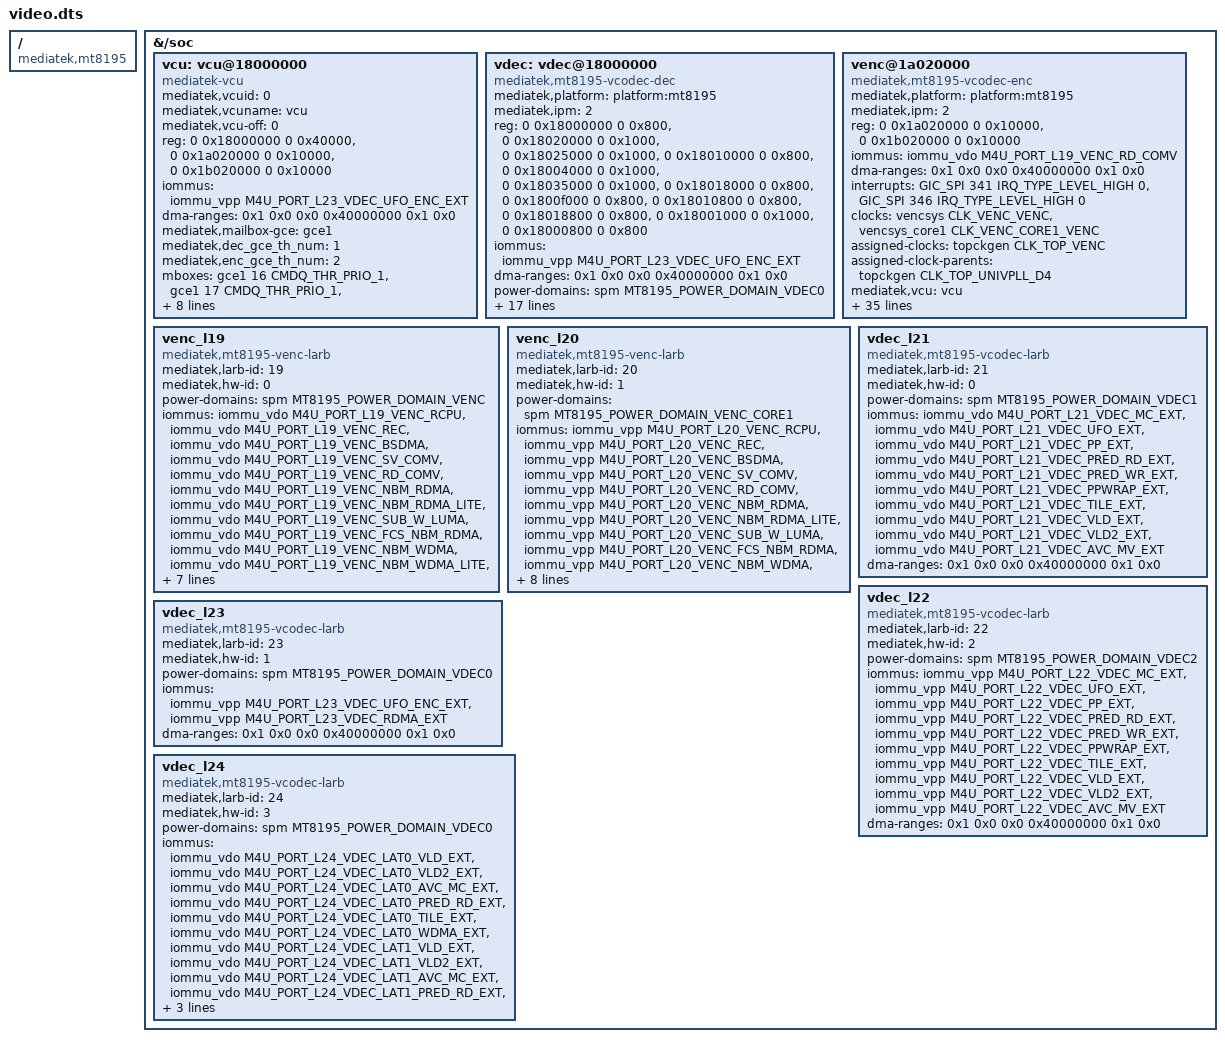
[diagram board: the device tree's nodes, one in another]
// SPDX-License-Identifier: (GPL-2.0 OR MIT)
/*
 * Copyright (c) 2021 MediaTek Inc.
 * Author: Macross Chen <macross.chen@mediatek.com>
 */

/dts-v1/;
/plugin/;

#include <dt-bindings/clock/mt8195-clk.h>
#include <dt-bindings/gce/mt8195-gce.h>
#include <dt-bindings/interrupt-controller/arm-gic.h>
#include <dt-bindings/interrupt-controller/irq.h>
#include <dt-bindings/memory/mt8195-memory-port.h>
#include <dt-bindings/power/mt8195-power.h>

/ {
	compatible = "mediatek,mt8195";
 
	fragment@0 {
		target-path = "/soc";
		__overlay__ {
			vcu: vcu@18000000 {
				compatible = "mediatek-vcu";
				mediatek,vcuid = <0>;
				mediatek,vcuname = "vcu";
				mediatek,vcu-off  = <0>;
				reg = <0 0x18000000 0 0x40000>,/* VDEC_BASE */
					  <0 0x1a020000 0 0x10000>,/* VENC_BASE */
					  <0 0x1b020000 0 0x10000>;/* VENC_C1_BASE */
				iommus = <&iommu_vpp M4U_PORT_L23_VDEC_UFO_ENC_EXT>;
				dma-ranges = <0x1 0x0 0x0 0x40000000 0x1 0x0>;
				mediatek,mailbox-gce = <&gce1>;
				mediatek,dec_gce_th_num = <1>;
				mediatek,enc_gce_th_num = <2>;
				mboxes = <&gce1 16 CMDQ_THR_PRIO_1>,
					 <&gce1 17 CMDQ_THR_PRIO_1>,
					 <&gce1 18 CMDQ_THR_PRIO_1>;
				gce-event-names = "venc_eof",
						  "venc_eof_c1",
						  "venc_wp_2nd_done",
						  "venc_wp_3nd_done";

				gce-events = <CMDQ_EVENT_VENC_TOP_FRAME_DONE>,
						 <CMDQ_EVENT_VENC_CORE1_TOP_FRAME_DONE>,
						 <CMDQ_EVENT_VENC_TOP_WP_2ND_STAGE_DONE>,
						 <CMDQ_EVENT_VENC_TOP_WP_3RD_STAGE_DONE>;

				gce-gpr = <GCE_GPR_R10>, <GCE_GPR_R11>;
			};

			vdec: vdec@18000000 {
				compatible = "mediatek,mt8195-vcodec-dec";
				mediatek,platform = "platform:mt8195";
				mediatek,ipm = <2>;
				reg =   <0 0x18000000 0 0x800>,/* VDEC_BASE */
					<0 0x18020000 0 0x1000>,/* VDEC_VLD */
					<0 0x18025000 0 0x1000>,/* VDEC_MISC */
					<0 0x18010000 0 0x800>,/* VDEC_LAT_MISC */
					<0 0x18004000 0 0x1000>,/* VDEC_RACING_CTRL */
					<0 0x18035000 0 0x1000>,/* VDEC_CORE1_MISC */
					<0 0x18018000 0 0x800>,/* VDEC_LAT1_MISC */
					<0 0x1800f000 0 0x800>,/* VDEC_SOC_GCON */
					<0 0x18010800 0 0x800>,/* VDEC_LAT_WDMA */
					<0 0x18018800 0 0x800>,/* VDEC_LAT1_WDMA */
					<0 0x18001000 0 0x1000>,/* VDEC_LAT_TOP */
					<0 0x18000800 0 0x800>;/* VDEC_UFO_ENC */
				reg-names = "VDEC_BASE",
					"VDEC_VLD",
					"VDEC_MISC",
					"VDEC_LAT_MISC",
					"VDEC_RACING_CTRL",
					"VDEC_CORE1_MISC",
					"VDEC_LAT1_MISC",
					"VDEC_SOC_GCON",
					"VDEC_LAT_WDMA",
					"VDEC_LAT1_WDMA",
					"VDEC_LAT_TOP",
					"VDEC_UFO_ENC";
				iommus = <&iommu_vpp M4U_PORT_L23_VDEC_UFO_ENC_EXT>;
				dma-ranges = <0x1 0x0 0x0 0x40000000 0x1 0x0>;
				power-domains = <&spm MT8195_POWER_DOMAIN_VDEC0>;/* SOC */
				interrupts = <GIC_SPI 707 IRQ_TYPE_LEVEL_HIGH 0>,
						 <GIC_SPI 708 IRQ_TYPE_LEVEL_HIGH 0>,
						 <GIC_SPI 709 IRQ_TYPE_LEVEL_HIGH 0>,
						 <GIC_SPI 710 IRQ_TYPE_LEVEL_HIGH 0>,
						 <GIC_SPI 711 IRQ_TYPE_LEVEL_HIGH 0>;
				clocks = <&vdecsys_soc CLK_VDEC_SOC_LARB1>,
					 <&vdecsys_soc CLK_VDEC_SOC_LAT>,
					 <&vdecsys_soc CLK_VDEC_SOC_VDEC>,
					 <&vdecsys CLK_VDEC_LARB1>,
					 <&vdecsys CLK_VDEC_VDEC>,
					 <&vdecsys_core1 CLK_VDEC_CORE1_LARB1>,
					 <&vdecsys_core1 CLK_VDEC_CORE1_VDEC>;
				clock-names = "SOC_MT_CG_LARB1",
					 "LAT_MT_CG_VDEC",
					 "SOC_MT_CG_VDEC",
					 "CORE_MT_CG_LARB1",
					 "CORE_MT_CG_VDEC",
					 "CORE_MT_CG_CORE1_LARB1",
					 "CORE_MT_CG_CORE1_VDEC";
				assigned-clocks = <&topckgen CLK_TOP_VDEC>;
				assigned-clock-parents = <&apmixedsys CLK_APMIXED_VDECPLL>;
				assigned-clock-rates = <680000000>;
				mediatek,vcu = <&vcu>;
			};

			venc@1a020000 {
				compatible = "mediatek,mt8195-vcodec-enc";
				mediatek,platform = "platform:mt8195";
				mediatek,ipm = <2>;
				reg = <0 0x1a020000 0 0x10000>,/* VENC_C0 */
					  <0 0x1b020000 0 0x10000>;/* VENC_C1 */
				reg-names = "VENC_SYS",
					"VENC_C1_SYS";
				iommus = <&iommu_vdo M4U_PORT_L19_VENC_RD_COMV>;
				dma-ranges = <0x1 0x0 0x0 0x40000000 0x1 0x0>;
				interrupts = <GIC_SPI 341 IRQ_TYPE_LEVEL_HIGH 0>,
						 <GIC_SPI 346 IRQ_TYPE_LEVEL_HIGH 0>;
				clocks = <&vencsys CLK_VENC_VENC>,
					 <&vencsys_core1 CLK_VENC_CORE1_VENC>;
				clock-names = "MT_CG_VENC0",
						  "MT_CG_VENC1";
				assigned-clocks = <&topckgen CLK_TOP_VENC>;
				assigned-clock-parents = <&topckgen CLK_TOP_UNIVPLL_D4>;
				mediatek,vcu = <&vcu>;

				port-arg-num = <3>;
				port-def = <0 M4U_PORT_L19_VENC_RCPU 0>,
					 <0 M4U_PORT_L19_VENC_REC 0>,
					 <0 M4U_PORT_L19_VENC_BSDMA 0>,
					 <0 M4U_PORT_L19_VENC_SV_COMV 0>,
					 <0 M4U_PORT_L19_VENC_RD_COMV 0>,
					 <0 M4U_PORT_L19_VENC_NBM_RDMA 1>,
					 <0 M4U_PORT_L19_VENC_NBM_RDMA_LITE 1>,
					 <0 M4U_PORT_L19_VENC_SUB_W_LUMA 0>,
					 <0 M4U_PORT_L19_VENC_FCS_NBM_RDMA 1>,
					 <0 M4U_PORT_L19_VENC_NBM_WDMA 1>,
					 <0 M4U_PORT_L19_VENC_NBM_WDMA_LITE 1>,
					 <0 M4U_PORT_L19_VENC_FCS_NBM_WDMA 1>,
					 <0 M4U_PORT_L19_VENC_CUR_LUMA 0>,
					 <0 M4U_PORT_L19_VENC_CUR_CHROMA 0>,
					 <0 M4U_PORT_L19_VENC_REF_LUMA 0>,
					 <0 M4U_PORT_L19_VENC_REF_CHROMA 0>,
					 <0 M4U_PORT_L19_VENC_SUB_R_CHROMA 0>,
					 <1 M4U_PORT_L20_VENC_RCPU 0>,
					 <1 M4U_PORT_L20_VENC_REC 0>,
					 <1 M4U_PORT_L20_VENC_BSDMA 0>,
					 <1 M4U_PORT_L20_VENC_SV_COMV 0>,
					 <1 M4U_PORT_L20_VENC_RD_COMV 0>,
					 <1 M4U_PORT_L20_VENC_NBM_RDMA 1>,
					 <1 M4U_PORT_L20_VENC_NBM_RDMA_LITE 1>,
					 <1 M4U_PORT_L20_VENC_SUB_W_LUMA 0>,
					 <1 M4U_PORT_L20_VENC_FCS_NBM_RDMA 1>,
					 <1 M4U_PORT_L20_VENC_NBM_WDMA 1>,
					 <1 M4U_PORT_L20_VENC_NBM_WDMA_LITE 1>,
					 <1 M4U_PORT_L20_VENC_FCS_NBM_WDMA 1>,
					 <1 M4U_PORT_L20_VENC_CUR_LUMA 0>,
					 <1 M4U_PORT_L20_VENC_CUR_CHROMA 0>,
					 <1 M4U_PORT_L20_VENC_REF_LUMA 0>,
					 <1 M4U_PORT_L20_VENC_REF_CHROMA 0>,
					 <1 M4U_PORT_L20_VENC_SUB_R_CHROMA 0>;
			};

			venc_l19 {
				compatible = "mediatek,mt8195-venc-larb";
				mediatek,larb-id = <19>;
				mediatek,hw-id = <0>;
				power-domains = <&spm MT8195_POWER_DOMAIN_VENC>;
				iommus = <&iommu_vdo M4U_PORT_L19_VENC_RCPU>,
					 <&iommu_vdo M4U_PORT_L19_VENC_REC>,
					 <&iommu_vdo M4U_PORT_L19_VENC_BSDMA>,
					 <&iommu_vdo M4U_PORT_L19_VENC_SV_COMV>,
					 <&iommu_vdo M4U_PORT_L19_VENC_RD_COMV>,
					 <&iommu_vdo M4U_PORT_L19_VENC_NBM_RDMA>,
					 <&iommu_vdo M4U_PORT_L19_VENC_NBM_RDMA_LITE>,
					 <&iommu_vdo M4U_PORT_L19_VENC_SUB_W_LUMA>,
					 <&iommu_vdo M4U_PORT_L19_VENC_FCS_NBM_RDMA>,
					 <&iommu_vdo M4U_PORT_L19_VENC_NBM_WDMA>,
					 <&iommu_vdo M4U_PORT_L19_VENC_NBM_WDMA_LITE>,
					 <&iommu_vdo M4U_PORT_L19_VENC_FCS_NBM_WDMA>,
					 <&iommu_vdo M4U_PORT_L19_VENC_CUR_LUMA>,
					 <&iommu_vdo M4U_PORT_L19_VENC_CUR_CHROMA>,
					 <&iommu_vdo M4U_PORT_L19_VENC_REF_LUMA>,
					 <&iommu_vdo M4U_PORT_L19_VENC_REF_CHROMA>,
					 <&iommu_vdo M4U_PORT_L19_VENC_SUB_R_CHROMA>;
				dma-ranges = <0x1 0x0 0x0 0x40000000 0x1 0x0>;
			};

			venc_l20 {
				compatible = "mediatek,mt8195-venc-larb";
				mediatek,larb-id = <20>;
				mediatek,hw-id = <1>;
				power-domains = <&spm MT8195_POWER_DOMAIN_VENC_CORE1>;
				iommus = <&iommu_vpp M4U_PORT_L20_VENC_RCPU>,
					 <&iommu_vpp M4U_PORT_L20_VENC_REC>,
					 <&iommu_vpp M4U_PORT_L20_VENC_BSDMA>,
					 <&iommu_vpp M4U_PORT_L20_VENC_SV_COMV>,
					 <&iommu_vpp M4U_PORT_L20_VENC_RD_COMV>,
					 <&iommu_vpp M4U_PORT_L20_VENC_NBM_RDMA>,
					 <&iommu_vpp M4U_PORT_L20_VENC_NBM_RDMA_LITE>,
					 <&iommu_vpp M4U_PORT_L20_VENC_SUB_W_LUMA>,
					 <&iommu_vpp M4U_PORT_L20_VENC_FCS_NBM_RDMA>,
					 <&iommu_vpp M4U_PORT_L20_VENC_NBM_WDMA>,
					 <&iommu_vpp M4U_PORT_L20_VENC_NBM_WDMA_LITE>,
					 <&iommu_vpp M4U_PORT_L20_VENC_FCS_NBM_WDMA>,
					 <&iommu_vpp M4U_PORT_L20_VENC_CUR_LUMA>,
					 <&iommu_vpp M4U_PORT_L20_VENC_CUR_CHROMA>,
					 <&iommu_vpp M4U_PORT_L20_VENC_REF_LUMA>,
					 <&iommu_vpp M4U_PORT_L20_VENC_REF_CHROMA>,
					 <&iommu_vpp M4U_PORT_L20_VENC_SUB_R_CHROMA>;
				dma-ranges = <0x1 0x0 0x0 0x40000000 0x1 0x0>;
			};

			vdec_l21 {
				compatible = "mediatek,mt8195-vcodec-larb";
				mediatek,larb-id = <21>;
				mediatek,hw-id = <0>;
				power-domains = <&spm MT8195_POWER_DOMAIN_VDEC1>;/* core0 */
				iommus = <&iommu_vdo M4U_PORT_L21_VDEC_MC_EXT>,
					 <&iommu_vdo M4U_PORT_L21_VDEC_UFO_EXT>,
					 <&iommu_vdo M4U_PORT_L21_VDEC_PP_EXT>,
					 <&iommu_vdo M4U_PORT_L21_VDEC_PRED_RD_EXT>,
					 <&iommu_vdo M4U_PORT_L21_VDEC_PRED_WR_EXT>,
					 <&iommu_vdo M4U_PORT_L21_VDEC_PPWRAP_EXT>,
					 <&iommu_vdo M4U_PORT_L21_VDEC_TILE_EXT>,
					 <&iommu_vdo M4U_PORT_L21_VDEC_VLD_EXT>,
					 <&iommu_vdo M4U_PORT_L21_VDEC_VLD2_EXT>,
					 <&iommu_vdo M4U_PORT_L21_VDEC_AVC_MV_EXT>;
				dma-ranges = <0x1 0x0 0x0 0x40000000 0x1 0x0>;
			};

			vdec_l22 {
				compatible = "mediatek,mt8195-vcodec-larb";
				mediatek,larb-id = <22>;
				mediatek,hw-id = <2>;
				power-domains = <&spm MT8195_POWER_DOMAIN_VDEC2>;/* core1 */
				iommus = <&iommu_vpp M4U_PORT_L22_VDEC_MC_EXT>,
					 <&iommu_vpp M4U_PORT_L22_VDEC_UFO_EXT>,
					 <&iommu_vpp M4U_PORT_L22_VDEC_PP_EXT>,
					 <&iommu_vpp M4U_PORT_L22_VDEC_PRED_RD_EXT>,
					 <&iommu_vpp M4U_PORT_L22_VDEC_PRED_WR_EXT>,
					 <&iommu_vpp M4U_PORT_L22_VDEC_PPWRAP_EXT>,
					 <&iommu_vpp M4U_PORT_L22_VDEC_TILE_EXT>,
					 <&iommu_vpp M4U_PORT_L22_VDEC_VLD_EXT>,
					 <&iommu_vpp M4U_PORT_L22_VDEC_VLD2_EXT>,
					 <&iommu_vpp M4U_PORT_L22_VDEC_AVC_MV_EXT>;
				dma-ranges = <0x1 0x0 0x0 0x40000000 0x1 0x0>;
			};

			vdec_l23 {
				compatible = "mediatek,mt8195-vcodec-larb";
				mediatek,larb-id = <23>;
				mediatek,hw-id = <1>;
				power-domains = <&spm MT8195_POWER_DOMAIN_VDEC0>;/* soc */
				iommus = <&iommu_vpp M4U_PORT_L23_VDEC_UFO_ENC_EXT>,
					 <&iommu_vpp M4U_PORT_L23_VDEC_RDMA_EXT>;
				dma-ranges = <0x1 0x0 0x0 0x40000000 0x1 0x0>;
			};

			vdec_l24 {
				compatible = "mediatek,mt8195-vcodec-larb";
				mediatek,larb-id = <24>;
				mediatek,hw-id = <3>;
				power-domains = <&spm MT8195_POWER_DOMAIN_VDEC0>;/* soc */
				iommus = <&iommu_vdo M4U_PORT_L24_VDEC_LAT0_VLD_EXT>,
					 <&iommu_vdo M4U_PORT_L24_VDEC_LAT0_VLD2_EXT>,
					 <&iommu_vdo M4U_PORT_L24_VDEC_LAT0_AVC_MC_EXT>,
					 <&iommu_vdo M4U_PORT_L24_VDEC_LAT0_PRED_RD_EXT>,
					 <&iommu_vdo M4U_PORT_L24_VDEC_LAT0_TILE_EXT>,
					 <&iommu_vdo M4U_PORT_L24_VDEC_LAT0_WDMA_EXT>,
					 <&iommu_vdo M4U_PORT_L24_VDEC_LAT1_VLD_EXT>,/*LAT1*/
					 <&iommu_vdo M4U_PORT_L24_VDEC_LAT1_VLD2_EXT>,
					 <&iommu_vdo M4U_PORT_L24_VDEC_LAT1_AVC_MC_EXT>,
					 <&iommu_vdo M4U_PORT_L24_VDEC_LAT1_PRED_RD_EXT>,
					 <&iommu_vdo M4U_PORT_L24_VDEC_LAT1_TILE_EXT>,
					 <&iommu_vdo M4U_PORT_L24_VDEC_LAT1_WDMA_EXT>;
				dma-ranges = <0x1 0x0 0x0 0x40000000 0x1 0x0>;
			};
		};
	};
};
